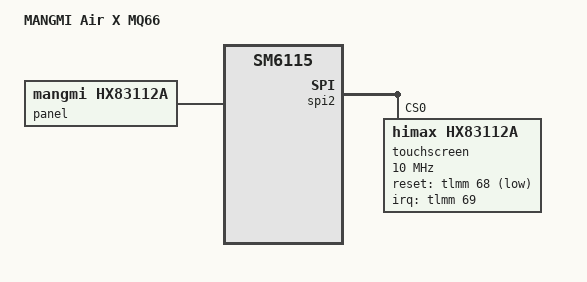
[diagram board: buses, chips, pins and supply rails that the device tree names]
// SPDX-License-Identifier: BSD-3-Clause
/*
 * Copyright (c) 2025, ROCKNIX
 */

/dts-v1/;

#include "sm6115-mangmi-air-x-base.dtsi"

/ {
	model = "MANGMI Air X MQ66";
	compatible = "mangmi,sm6115-air-x-mq66", "qcom,sm6115";
};

&panel {
	compatible = "mangmi,hx83112a";
};

&spi2 {
	touchscreen@0 {
		compatible = "himax,hx83112a";
		reg = <0>;
		spi-max-frequency = <10000000>;

		interrupt-parent = <&tlmm>;
		interrupts = <69 IRQ_TYPE_LEVEL_LOW>;
		reset-gpios = <&tlmm 68 GPIO_ACTIVE_LOW>;

		touchscreen-size-x = <1080>;
		touchscreen-size-y = <1920>;

		pinctrl-names = "default";
		pinctrl-0 = <&ts_irq_default>;
	};
};
